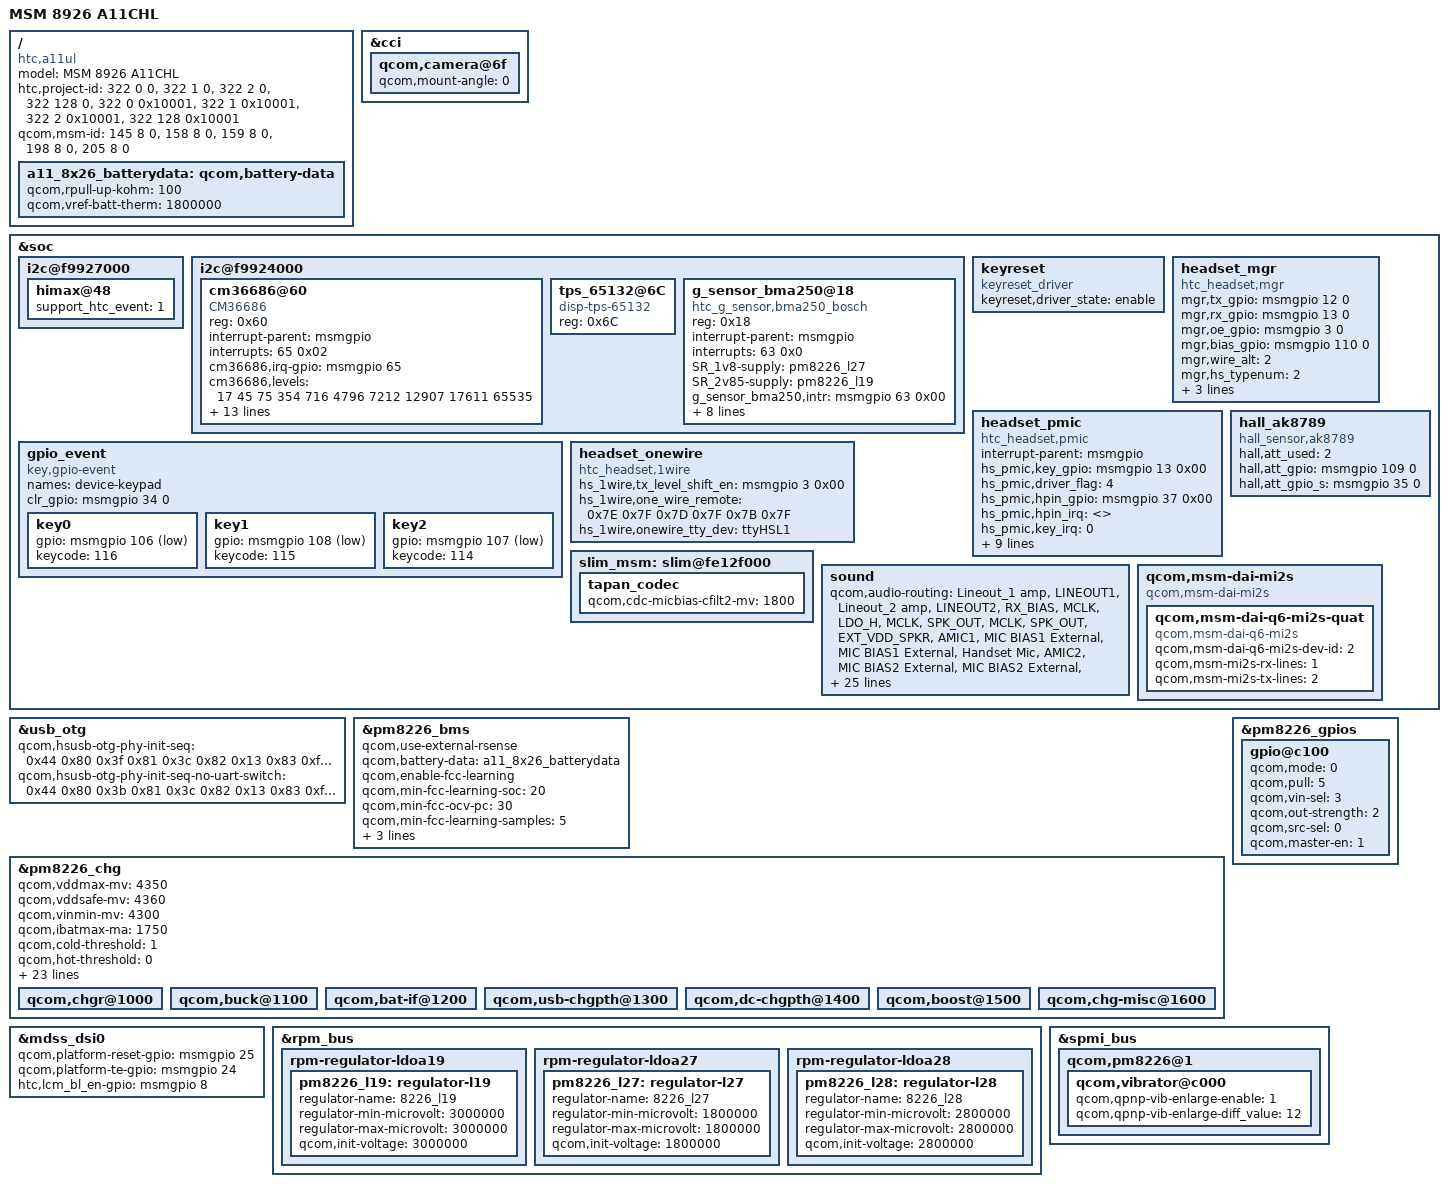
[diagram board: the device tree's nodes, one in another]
/* Copyright (c) 2013, The Linux Foundation. All rights reserved.
 *
 * This program is free software; you can redistribute it and/or modify
 * it under the terms of the GNU General Public License version 2 and
 * only version 2 as published by the Free Software Foundation.
 *
 * This program is distributed in the hope that it will be useful,
 * but WITHOUT ANY WARRANTY; without even the implied warranty of
 * MERCHANTABILITY or FITNESS FOR A PARTICULAR PURPOSE.  See the
 * GNU General Public License for more details.
 */

/dts-v1/;
/include/ "msm8926-1G.dtsi"
/include/ "msm8226-720p-mtp.dtsi"
/include/ "msm8226-camera-sensor-A11CHL.dtsi"
/include/ "dsi-panel-a11.dtsi"
/include/ "msm8226-a11ul-storage.dtsi"
/include/ "msm8926-touch-a11-config.dtsi"
/include/ "msm8926-remove-cp-mm.dtsi"

/ {
	model = "MSM 8926 A11CHL";
	compatible = "htc,a11ul", "qcom,msm8926-mtp", "qcom,msm8926", "qcom,mtp";
	htc,project-id = <322 0 0>, <322 1 0>, <322 2 0>, <322 128 0>, <322 0 0x10001>, <322 1 0x10001>, <322 2 0x10001>, <322 128 0x10001>;  /* <pid hw-version reserve> */
	qcom,msm-id = <145 8 0>,
		      <158 8 0>,
		      <159 8 0>,
		      <198 8 0>,
		      <205 8 0>;
};

&cci {
	/* Rotate rear camera to 0 degrees */
	qcom,camera@6f {
	qcom,mount-angle = <0>;
	};
};

&soc {

	i2c@f9927000 { /* BLSP1 QUP5 */
	himax@48 {
			support_htc_event		= <1>;
			};
		};

	i2c@f9924000 {
		cm36686@60 {
			compatible = "CM36686";
			reg = <0x60>;
			interrupt-parent = <&msmgpio>;
			interrupts = <65 0x02>;
			interrupt-names = "cm36686";
			cm36686,irq-gpio = <&msmgpio 65 0x00>;
			cm36686,levels = <17 45 75 354 716 4796 7212 12907 17611 65535>;
			cm36686,golden_adc = <0x10CF>;
			cm36686,cm36686_slave_address = <0x60>;
			cm36686,ps1_thd_set = <0x15>;
			cm36686,ps1_thd_no_cal = <0x5f>;
			cm36686,dynamical_threshold = <1>;
			cm36686,dark_level = <3>;
			cm36686,ps_duty = <0>;
			cm36686,ps_pers = <1>;
			cm36686,ps_it = <7>;
			cm36686,ps_hd = <0>;
			cm36686,ps_led_current = <2>;
			SR_2v85-supply = <&pm8226_l19>;
			cm36686,SR_3v_used = <1>;
		};
	};


	i2c@f9924000 {
		tps_65132@6C {
			compatible = "disp-tps-65132";
			reg = <0x6C>;
		};
	};

	i2c@f9924000 {
		g_sensor_bma250@18 {
			compatible = "htc_g_sensor,bma250_bosch";
			reg = <0x18>;
			interrupt-parent = <&msmgpio>;
			interrupts = <63 0x0>;
			SR_1v8-supply = <&pm8226_l27>;
			SR_2v85-supply = <&pm8226_l19>;
			g_sensor_bma250,intr        = <&msmgpio 63 0x00>;
			g_sensor_bma250,chip_layout = <0>;
			g_sensor_bma250,axis_map_x  = <0>;
			g_sensor_bma250,axis_map_y  = <1>;
			g_sensor_bma250,axis_map_z  = <2>;
			g_sensor_bma250,negate_x    = <1>;
			g_sensor_bma250,negate_y    = <1>;
			g_sensor_bma250,negate_z    = <0>;
			g_sensor_bma250,SR_3v_used = <1>;
		};
	};

	gpio_event {
		compatible = "key,gpio-event";
		names = "device-keypad";
		clr_gpio = <&msmgpio 34 0>;

		key0 {
			gpio    = <&msmgpio 106 3>;
			keycode = <116>;	//pwr
		};
		key1 {
			gpio    = <&msmgpio 108 3>;
			keycode = <115>;	//vUP
		};
		key2 {
			gpio    = <&msmgpio 107 3>;
			keycode = <114>;	//vDN
		};
	};

	keyreset {
		compatible = "keyreset_driver";
		keyreset,driver_state = "enable";
	};

	headset_mgr {
		compatible   = "htc_headset,mgr";
		mgr,tx_gpio  = <&msmgpio 12 0>;
		mgr,rx_gpio  = <&msmgpio 13 0>;
		mgr,oe_gpio  = <&msmgpio 3 0>;
		mgr,bias_gpio  = <&msmgpio 110 0>;
		mgr,wire_alt = <2>;
		mgr,hs_typenum   = <2>;
		mgr,hs_type      = <2 1>;
		mgr,adc_max      = <1557 254>;
		mgr,adc_min      = <255 0>;
	};

	headset_pmic {
		compatible = "htc_headset,pmic";
		interrupt-parent = <&msmgpio>;
		hs_pmic,key_gpio 	= <&msmgpio 13 0x00>;
		hs_pmic,driver_flag     = <4>;
		hs_pmic,hpin_gpio       = <&msmgpio 37 0x00>;
		hs_pmic,hpin_irq        = <>;
		hs_pmic,key_irq         = <0>;
		hs_pmic,key_enable_gpio = <0>;
		hs_pmic,adc_mic         = <0>;
		hs_pmic,adc_remote      = <0 56 57 146 147 339>;
		hs_pmic,adc_channel	= <17>;		//P_MUX2_1_1
		hs_pmic,adc_mpp         = <0>;
		hs_pmic,adc_amux        = <0>;
		hs_pmic,hs_controller   = <0>;
		hs_pmic,hs_switch       = <0>;
		qcom,headset-vadc	= <&pm8226_vadc>;
	};

	headset_onewire {
		compatible = "htc_headset,1wire";
		hs_1wire,tx_level_shift_en = <&msmgpio 3 0x00>;
		hs_1wire,one_wire_remote = <0x7E 0x7F 0x7D 0x7F 0x7B 0x7F>;
		hs_1wire,onewire_tty_dev = "ttyHSL1";
	};

	hall_ak8789 {
		compatible = "hall_sensor,ak8789";
		hall,att_used = <2>;
		hall,att_gpio = <&msmgpio 109 0>;
		hall,att_gpio_s = <&msmgpio 35 0>;
	};

/*Audio config start*/
	slim_msm: slim@fe12f000 {
		tapan_codec {
			qcom,cdc-micbias-cfilt2-mv = <1800>;
		};
	};

	sound {
		qcom,audio-routing =
			"Lineout_1 amp", "LINEOUT1",
			"Lineout_2 amp", "LINEOUT2",
			"RX_BIAS", "MCLK",
			"LDO_H", "MCLK",
			"SPK_OUT", "MCLK",
			"SPK_OUT", "EXT_VDD_SPKR",
			"AMIC1", "MIC BIAS1 External",
			"MIC BIAS1 External", "Handset Mic",
			"AMIC2", "MIC BIAS2 External",
			"MIC BIAS2 External", "Headset Mic",
			"AMIC3", "MIC BIAS2 External",
			"MIC BIAS2 External", "Handset Mic",
			"AMIC4", "MIC BIAS2 External",
			"MIC BIAS2 External", "ANCRight Headset Mic",
			"AMIC5", "MIC BIAS2 External",
			"MIC BIAS2 External", "ANCLeft Headset Mic";

		qcom,cdc-mclk-gpios = <&pm8226_gpios 1 0>;
		qcom,cdc-vdd-spkr-gpios = <>;

		qcom,prim-auxpcm-gpio-clk  = <>;
		qcom,prim-auxpcm-gpio-sync = <>;
		qcom,prim-auxpcm-gpio-din  = <>;
		qcom,prim-auxpcm-gpio-dout = <>;
		qcom,sec-auxpcm-gpio-clk  = <>;
		qcom,sec-auxpcm-gpio-sync = <>;
		qcom,sec-auxpcm-gpio-din  = <>;
		qcom,sec-auxpcm-gpio-dout = <>;

		mi2s-gpio-sck   = <&msmgpio 49 0>;
		mi2s-gpio-ws    = <&msmgpio 50 0>;
		mi2s-gpio-sda0  = <&msmgpio 51 0>;
		mi2s-gpio-sda1  = <&msmgpio 52 0>;
		mi2s-afe-portid = <0x1004>;

		rcv-gpio-sel    = <&msmgpio 0 0>;
		rcv-gpio-en     = <&msmgpio 69 0>;

		htc,aud-digital-mic-en = <0>;
		htc,aud-24b-en = <1>;
	};

	qcom,msm-dai-mi2s {
		compatible = "qcom,msm-dai-mi2s";
		qcom,msm-dai-q6-mi2s-quat {
			compatible = "qcom,msm-dai-q6-mi2s";
			qcom,msm-dai-q6-mi2s-dev-id = <2>;
			qcom,msm-mi2s-rx-lines = <1>;
			qcom,msm-mi2s-tx-lines = <2>;
		};
	};
/*Audio config end*/
};


&usb_otg {
    qcom,hsusb-otg-phy-init-seq =
            <0x44 0x80 0x3f 0x81 0x3c 0x82 0x13 0x83 0xffffffff>;
    qcom,hsusb-otg-phy-init-seq-no-uart-switch =
            <0x44 0x80 0x3b 0x81 0x3c 0x82 0x13 0x83 0xffffffff>;
};

&pm8226_bms {
	qcom,use-external-rsense;
	qcom,battery-data = <&a11_8x26_batterydata>;
	qcom,enable-fcc-learning;
	qcom,min-fcc-learning-soc = <20>;
	qcom,min-fcc-ocv-pc = <30>;
	qcom,min-fcc-learning-samples = <5>;
	qcom,fcc-resolution = <13>;
	qcom,enable-sw-ocv-in-eoc = <1>;
	qcom,enable-batt-full-fake-ocv = <1>;
	status = "ok";
};

&pm8226_chg {
	qcom,vddmax-mv = <4350>;
	qcom,vddsafe-mv = <4360>;
	qcom,vinmin-mv = <4300>;
	qcom,ibatmax-ma = <1750>;
	qcom,cold-threshold = <1>;
	qcom,hot-threshold = <0>;
	qcom,ibatterm-ma = <180>;
	qcom,ibatsafe-ma = <1750>;
	qcom,thermal-mitigation = <1500 700 600 325>;
	qcom,cool-bat-decidegc = <0>;
	qcom,cool-bat-mv = <4350>;
	qcom,ibatmax-warm-ma = <1750>;
	qcom,warm-bat-decidegc = <480>;
	qcom,warm-bat-mv = <4000>;
	qcom,ibatmax-cool-ma = <1750>;
	qcom,vbatdet-delta-mv = <50>;
	qcom,resume-soc = <99>;
	qcom,tchg-mins = <960>;
	qcom,batt-hot-percentage = <25>;
	qcom,batt-cold-percentage = <80>;
	qcom,chg-vadc = <&pm8226_vadc>;
	qcom,chg-adc_tm = <&pm8226_adc_tm>;
	qcom,eoc-ibat-thre-ma = <50>;
	qcom,is-embeded-batt = <1>;
	qcom,stored-pre-delta-vddmax-mv= <(-1)>;
	qcom,stored-batt-magic-num= <(-1)>;

	status = "ok";
	qcom,charging-disabled;
	qcom,enable-qct-adjust-vddmax;
	htc,enable-sw-idic-algo;

	qcom,chgr@1000 {
		status = "ok";
	};

	qcom,buck@1100 {
		status = "ok";
	};

	qcom,bat-if@1200 {
		status = "ok";
	};

	qcom,usb-chgpth@1300 {
		status = "ok";
	};

	qcom,dc-chgpth@1400 {
		status = "ok";
	};

	qcom,boost@1500 {
		status = "ok";
	};

	qcom,chg-misc@1600 {
		status = "ok";
	};
};

/ {
	a11_8x26_batterydata: qcom,battery-data {
		qcom,rpull-up-kohm = <100>;
		qcom,vref-batt-therm = <1800000>;

			/include/ "batterydata-a11-8x26-id1.dtsi"
			/include/ "batterydata-a11-8x26-id2.dtsi"
			/include/ "batterydata-a11-8x26-unknown-id.dtsi"
	};
};

&mdss_dsi0 {
	qcom,platform-reset-gpio = <&msmgpio 25 0>;
	qcom,platform-te-gpio = <&msmgpio 24 0>;
	htc,lcm_bl_en-gpio = <&msmgpio 8 0>;
};
&rpm_bus {
	rpm-regulator-ldoa19 {
		status = "okay";
		pm8226_l19: regulator-l19 {
			regulator-name = "8226_l19";
			regulator-min-microvolt = <3000000>;
			regulator-max-microvolt = <3000000>;
			qcom,init-voltage = <3000000>;
			status = "okay";
		};
	};
	rpm-regulator-ldoa27 {
		status = "okay";
		pm8226_l27: regulator-l27 {
			regulator-name = "8226_l27";
			regulator-min-microvolt = <1800000>;
			regulator-max-microvolt = <1800000>;
			qcom,init-voltage = <1800000>;
			status = "okay";
		};
	};
	rpm-regulator-ldoa28 {
		status = "okay";
		pm8226_l28: regulator-l28 {
			regulator-name = "8226_l28";
			regulator-min-microvolt = <2800000>;
			regulator-max-microvolt = <2800000>;
			qcom,init-voltage = <2800000>;
			status = "okay";
		};
	};
};

&pm8226_gpios {
	/* GPIO_RD_R enable for batt id */
	gpio@c100 { /* GPIO 2 */
		qcom,mode = <0>;                /* Digital input */
		qcom,pull = <5>;                /* QPNP_PIN_PULL_NO */
		qcom,vin-sel = <3>;             /* QPNP_PIN_VIN3 (1.8V) */
		qcom,out-strength = <2>;        /* QPNP_PIN_OUT_STRENGTH_MED */
		qcom,src-sel = <0>;             /* QPNP_PIN_SEL_FUNC_CONSTANT */
		qcom,master-en = <1>;           /* Enable GPIO */
	};
};

&spmi_bus {
        qcom,pm8226@1 {
                qcom,vibrator@c000 {
                        qcom,qpnp-vib-enlarge-enable = <1>;
                        qcom,qpnp-vib-enlarge-diff_value = <12>;
                };
        };
};
